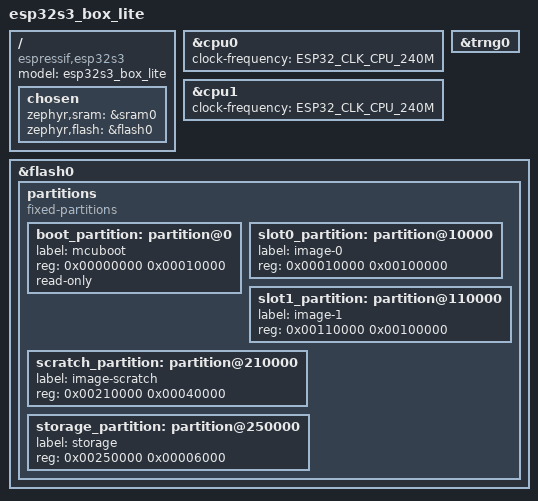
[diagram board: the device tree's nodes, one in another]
/*
 * Copyright (c) 2022 Espressif Systems (Shanghai) Co., Ltd.
 *
 * SPDX-License-Identifier: Apache-2.0
 */
/dts-v1/;

#include <espressif/esp32s3.dtsi>
#include "esp32s3_box_lite-pinctrl.dtsi"

/ {
	model = "esp32s3_box_lite";
	compatible = "espressif,esp32s3";

	chosen {
		zephyr,sram = &sram0;
		zephyr,flash = &flash0;
		// zephyr,display = &st7789v;
	};

	// aliases {
	// 	sw0 = &button0;
	// };

	// buttons {
	// 	compatible = "gpio-keys";
	// 	button0: button_0 {
	// 		gpios = <&gpio0 0 (GPIO_PULL_UP | GPIO_ACTIVE_LOW)>;
	// 		label = "BOOT Button";
	// 	};
	// };

	// zephyr,user {
	// 	io-channels = <&adc0 0>;
	// };
};

&cpu0 {
	clock-frequency = <ESP32_CLK_CPU_240M>;
};

&cpu1 {
	clock-frequency = <ESP32_CLK_CPU_240M>;
};

// &usb_serial {
// 	status = "okay";
// };

// &uart0 {
// 	status = "okay";
// 	current-speed = <115200>;
// 	pinctrl-0 = <&uart0_default>;
// 	pinctrl-names = "default";
// };

// &gpio0 {
// 	status = "okay";
// };

// &gpio1 {
// 	status = "okay";
// };

// &i2c0 {
// 	clock-frequency = <I2C_BITRATE_STANDARD>;
// 	pinctrl-0 = <&i2c0_default>;
// 	pinctrl-names = "default";
// };

// &i2c1 {
// 	clock-frequency = <I2C_BITRATE_STANDARD>;
// 	pinctrl-0 = <&i2c1_default>;
// 	pinctrl-names = "default";
// };

// &spi3 {
// 	#address-cells = <1>;
// 	#size-cells = <0>;
// 	status = "okay";
// 	pinctrl-0 = <&spim3_default>;
// 	pinctrl-names = "default";

// 		/* Sitronix ST7789V LCD */
// 	st7789v: st7789v@0 {
// 		compatible = "sitronix,st7789v";
// 		reg = <0>;
// 		spi-max-frequency = <80000000>; /* 8MHz */
// 		cmd-data-gpios = <&gpio0 4 GPIO_ACTIVE_LOW>;	/* DET */
// 		reset-gpios = <&gpio1 16 GPIO_ACTIVE_LOW>;	/* RESX reset */

// 		// landscape
// 		width = <320>;
// 		height = <240>;
// 		x-offset = <0>;
// 		y-offset = <0>;
// 		mdac = <0xA7>;

// 		vcom = <0x19>;
// 		gctrl = <0x35>;
// 		vrhs = <0x12>;
// 		vdvs = <0x20>;
// 		gamma = <0x01>;
// 		colmod = <0x05>;
// 		lcm = <0x2c>;
// 		porch-param = [0c 0c 00 33 33];
// 		cmd2en-param = [5a 69 02 01];
// 		pwctrl1-param = [a4 a1];
// 		pvgam-param = [D0 04 0D 11 13 2B 3F 54 4C 18 0D 0B 1F 23];
// 		nvgam-param = [D0 04 0C 11 13 2C 3F 44 51 2F 1F 1F 20 23];
// 		ram-param = [00 F0];
// 		rgb-param = [CD 08 14];
// 	};
// };

// &timer0 {
// 	status = "disabled";
// };

// &timer1 {
// 	status = "disabled";
// };

// &timer2 {
// 	status = "disabled";
// };

// &timer3 {
// 	status = "disabled";
// };

// &wdt0 {
// 	status = "okay";
// };

&trng0 {
	status = "okay";
};

// &adc0 {
// 	status = "okay";
// 	#address-cells = <1>;
// 	#size-cells = <0>;

// 	channel@0 {
// 		reg = <0>;
// 		zephyr,gain = "ADC_GAIN_1_4";
// 		zephyr,reference = "ADC_REF_INTERNAL";
// 		zephyr,acquisition-time = <ADC_ACQ_TIME_DEFAULT>;
// 		zephyr,resolution = <13>;
// 	};
// };

&flash0 {
	status = "okay";
	partitions {
		compatible = "fixed-partitions";
		#address-cells = <1>;
		#size-cells = <1>;

		/* Reserve 64kB for the bootloader */
		boot_partition: partition@0 {
			label = "mcuboot";
			reg = <0x00000000 0x00010000>;
			read-only;
		};

		/* Reserve 1024kB for the application in slot 0 */
		slot0_partition: partition@10000 {
			label = "image-0";
			reg = <0x00010000 0x00100000>;
		};

		/* Reserve 1024kB for the application in slot 1 */
		slot1_partition: partition@110000 {
			label = "image-1";
			reg = <0x00110000 0x00100000>;
		};

		/* Reserve 256kB for the scratch partition */
		scratch_partition: partition@210000 {
			   label = "image-scratch";
			   reg = <0x00210000 0x00040000>;
		};

		storage_partition: partition@250000 {
			label = "storage";
			reg = <0x00250000 0x00006000>;
		};
	};
};
